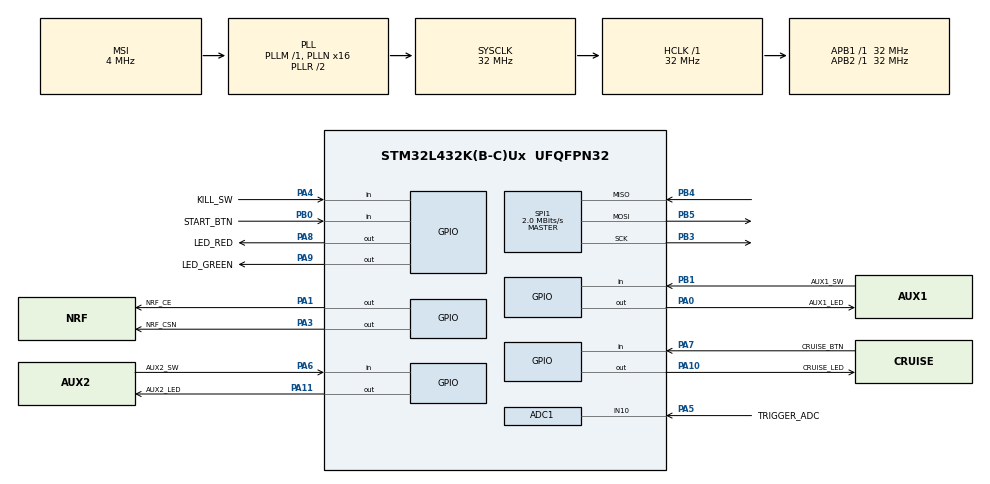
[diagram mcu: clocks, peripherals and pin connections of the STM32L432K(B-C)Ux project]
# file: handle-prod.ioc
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ADC1.Channel-0\#ChannelRegularConversion=ADC_CHANNEL_10
ADC1.NbrOfConversionFlag=1
ADC1.OffsetNumber-0\#ChannelRegularConversion=ADC_OFFSET_NONE
ADC1.Rank-0\#ChannelRegularConversion=1
ADC1.SamplingTime-0\#ChannelRegularConversion=ADC_SAMPLETIME_640CYCLES_5
ADC1.master=1
Mcu.Family=STM32L4
Mcu.Name=STM32L432K(B-C)Ux
Mcu.Package=UFQFPN32
NVIC.PriorityGroup=NVIC_PRIORITYGROUP_4
PA0.GPIO_Label=AUX1_LED
PA0.Signal=GPIO_Output
PA1.GPIO_Label=NRF_CE
PA1.Signal=GPIO_Output
PA10.GPIO_Label=CRUISE_LED
PA10.Signal=GPIO_Output
PA11.GPIO_Label=AUX2_LED
PA11.Signal=GPIO_Output
PA13\ (JTMS-SWDIO).GPIO_Label=SWDIO
PA13\ (JTMS-SWDIO).Signal=SYS_JTMS-SWDIO
PA14\ (JTCK-SWCLK).GPIO_Label=SWCLK
PA14\ (JTCK-SWCLK).Signal=SYS_JTCK-SWCLK
PA15\ (JTDI).GPIO_Label=VCP_RX
PA15\ (JTDI).Signal=USART2_RX
PA2.GPIO_Label=VCP_TX
PA2.Signal=USART2_TX
PA3.GPIO_Label=NRF_CSN
PA3.Signal=GPIO_Output
PA4.GPIO_Label=KILL_SW
PA4.GPIO_PuPd=GPIO_PULLUP
PA4.Signal=GPIO_Input
PA5.GPIO_Label=TRIGGER_ADC
PA5.Signal=ADCx_IN10
PA6.GPIO_Label=AUX2_SW
PA6.GPIO_PuPd=GPIO_PULLDOWN
PA6.Signal=GPIO_Input
PA7.GPIO_Label=CRUISE_BTN
PA7.GPIO_PuPd=GPIO_PULLDOWN
PA7.Signal=GPIO_Input
PA8.GPIO_Label=LED_RED
PA8.Signal=GPIO_Output
PA9.GPIO_Label=LED_GREEN
PA9.Signal=GPIO_Output
PB0.GPIO_Label=START_BTN
PB0.GPIO_PuPd=GPIO_PULLUP
PB0.Signal=GPIO_Input
PB1.GPIO_Label=AUX1_SW
PB1.GPIO_PuPd=GPIO_PULLDOWN
PB1.Signal=GPIO_Input
PB3\ (JTDO-TRACESWO).Mode=Full_Duplex_Master
PB3\ (JTDO-TRACESWO).Signal=SPI1_SCK
PB4\ (NJTRST).Mode=Full_Duplex_Master
PB4\ (NJTRST).Signal=SPI1_MISO
PB5.Mode=Full_Duplex_Master
PB5.Signal=SPI1_MOSI
PC14-OSC32_IN\ (PC14).Signal=RCC_OSC32_IN
PC15-OSC32_OUT\ (PC15).Signal=RCC_OSC32_OUT
ProjectManager.HeapSize=0x200
ProjectManager.StackSize=0x400
ProjectManager.TargetToolchain=STM32CubeIDE
RCC.ADCFreq_Value=32000000
RCC.AHBFreq_Value=32000000
RCC.APB1Freq_Value=32000000
RCC.APB1TimFreq_Value=32000000
RCC.APB2Freq_Value=32000000
RCC.APB2TimFreq_Value=32000000
RCC.CortexFreq_Value=32000000
RCC.HCLKFreq_Value=32000000
RCC.HSE_VALUE=8000000
RCC.HSI16_VALUE=16000000
RCC.HSI48_VALUE=48000000
RCC.HSI_VALUE=16000000
RCC.LSE_VALUE=32768
RCC.MSI_VALUE=4000000
RCC.PLLMUL=RCC_PLLMUL_4
RCC.PLLN=16
RCC.PLLSAI1N=16
RCC.SYSCLKFreq_VALUE=32000000
RCC.SYSCLKSource=RCC_SYSCLKSOURCE_PLLCLK
RCC.USBFreq_Value=32000000
RCC.VCOOutputFreq_Value=64000000
SH.ADCx_IN10.0=ADC1_IN10,IN10-Single-Ended
SPI1.BaudRatePrescaler=SPI_BAUDRATEPRESCALER_16
SPI1.CalculateBaudRate=2.0 MBits/s
SPI1.DataSize=SPI_DATASIZE_8BIT
SPI1.Direction=SPI_DIRECTION_2LINES
SPI1.Mode=SPI_MODE_MASTER
SPI1.VirtualType=VM_MASTER
board=NUCLEO-L432KC

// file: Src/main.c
/* USER CODE BEGIN Header */
/**
  ******************************************************************************
  * @file           : main.c
  * @brief          : Main program body
  ******************************************************************************
  * @attention
  *
  * Copyright (c) 2026 STMicroelectronics.
  * All rights reserved.
  *
  * This software is licensed under terms that can be found in the LICENSE file
  * in the root directory of this software component.
  * If no LICENSE file comes with this software, it is provided AS-IS.
  *
  ******************************************************************************
  */
/* USER CODE END Header */
#include "main.h"
#include "adc.h"
#include "spi.h"
#include "gpio.h"

/* USER CODE BEGIN Includes */
#include "handle_app.h"
/* USER CODE END Includes */

void SystemClock_Config(void);

int main(void)
{

  /* MCU Configuration--------------------------------------------------------*/

  /* Reset of all peripherals, Initializes the Flash interface and the Systick. */
  HAL_Init();

  /* Configure the system clock */
  SystemClock_Config();

  /* Initialize all configured peripherals */
  MX_GPIO_Init();
  MX_ADC1_Init();
  MX_SPI1_Init();
  /* USER CODE BEGIN 2 */
  handle_app_init();
  /* USER CODE END 2 */

  /* Infinite loop */
  while (1)
  {

    /* USER CODE BEGIN 3 */
    handle_app_tick();
  }
  /* USER CODE END 3 */
}

void SystemClock_Config(void)
{
  RCC_OscInitTypeDef RCC_OscInitStruct = {0};
  RCC_ClkInitTypeDef RCC_ClkInitStruct = {0};

  /** Configure the main internal regulator output voltage
  */
  if (HAL_PWREx_ControlVoltageScaling(PWR_REGULATOR_VOLTAGE_SCALE1) != HAL_OK)
  {
    Error_Handler();
  }

  /** Initializes the RCC Oscillators according to the specified parameters
  * in the RCC_OscInitTypeDef structure.
  */
  RCC_OscInitStruct.OscillatorType = RCC_OSCILLATORTYPE_MSI;
  RCC_OscInitStruct.MSIState = RCC_MSI_ON;
  RCC_OscInitStruct.MSICalibrationValue = 0;
  RCC_OscInitStruct.MSIClockRange = RCC_MSIRANGE_6;
  RCC_OscInitStruct.PLL.PLLState = RCC_PLL_ON;
  RCC_OscInitStruct.PLL.PLLSource = RCC_PLLSOURCE_MSI;
  RCC_OscInitStruct.PLL.PLLM = 1;
  RCC_OscInitStruct.PLL.PLLN = 16;
  RCC_OscInitStruct.PLL.PLLP = RCC_PLLP_DIV7;
  RCC_OscInitStruct.PLL.PLLQ = RCC_PLLQ_DIV2;
  RCC_OscInitStruct.PLL.PLLR = RCC_PLLR_DIV2;
  if (HAL_RCC_OscConfig(&RCC_OscInitStruct) != HAL_OK)
  {
    Error_Handler();
  }

  /** Initializes the CPU, AHB and APB buses clocks
  */
  RCC_ClkInitStruct.ClockType = RCC_CLOCKTYPE_HCLK|RCC_CLOCKTYPE_SYSCLK
                              |RCC_CLOCKTYPE_PCLK1|RCC_CLOCKTYPE_PCLK2;
  RCC_ClkInitStruct.SYSCLKSource = RCC_SYSCLKSOURCE_PLLCLK;
  RCC_ClkInitStruct.AHBCLKDivider = RCC_SYSCLK_DIV1;
  RCC_ClkInitStruct.APB1CLKDivider = RCC_HCLK_DIV1;
  RCC_ClkInitStruct.APB2CLKDivider = RCC_HCLK_DIV1;

  if (HAL_RCC_ClockConfig(&RCC_ClkInitStruct, FLASH_LATENCY_1) != HAL_OK)
  {
    Error_Handler();
  }
}

void Error_Handler(void)
{
  __disable_irq();
  while (1)
  {
  }
}
